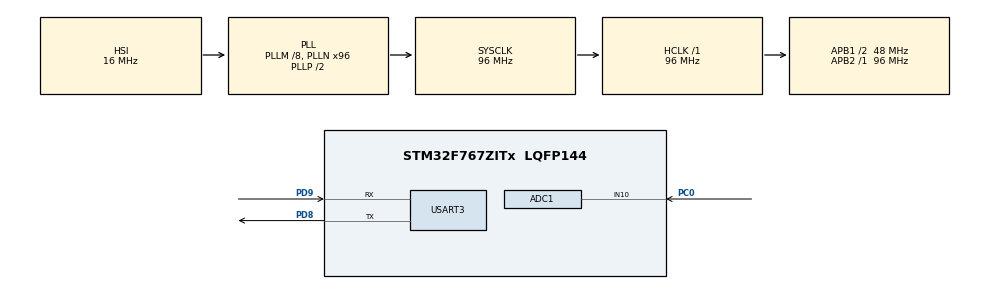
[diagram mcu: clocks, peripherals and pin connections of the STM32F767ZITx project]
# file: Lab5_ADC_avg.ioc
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ADC1.Channel-0\#ChannelRegularConversion=ADC_CHANNEL_10
ADC1.ContinuousConvMode=ENABLE
ADC1.EOCSelection=ADC_EOC_SEQ_CONV
ADC1.NbrOfConversionFlag=1
ADC1.Rank-0\#ChannelRegularConversion=1
ADC1.SamplingTime-0\#ChannelRegularConversion=ADC_SAMPLETIME_3CYCLES
ADC1.master=1
Mcu.Family=STM32F7
Mcu.Name=STM32F767ZITx
Mcu.Package=LQFP144
NVIC.PriorityGroup=NVIC_PRIORITYGROUP_4
PC0.Signal=SharedAnalog_PC0
PD8.Mode=Asynchronous
PD8.Signal=USART3_TX
PD9.Mode=Asynchronous
PD9.Signal=USART3_RX
ProjectManager.HeapSize=0x200
ProjectManager.StackSize=0x400
ProjectManager.TargetToolchain=STM32CubeIDE
RCC.48MHZClocksFreq_Value=24000000
RCC.AHBFreq_Value=96000000
RCC.APB1CLKDivider=RCC_HCLK_DIV2
RCC.APB1Freq_Value=48000000
RCC.APB1TimFreq_Value=96000000
RCC.APB2Freq_Value=96000000
RCC.APB2TimFreq_Value=96000000
RCC.CortexFreq_Value=96000000
RCC.HCLKFreq_Value=96000000
RCC.HSE_VALUE=8000000
RCC.HSI_VALUE=16000000
RCC.LSE_VALUE=32768
RCC.PLLM=8
RCC.PLLMUL=RCC_PLL_MUL9
RCC.PLLN=96
RCC.PLLQ=4
RCC.PRESCALERUSB=RCC_USBCLKSOURCE_PLL_DIV1_5
RCC.SYSCLKFreq_VALUE=96000000
RCC.SYSCLKSource=RCC_SYSCLKSOURCE_PLLCLK
RCC.SYSCLKSourceVirtual=RCC_SYSCLKSOURCE_PLLCLK
RCC.USBFreq_Value=48000000
RCC.VCOOutputFreq_Value=192000000
SH.SharedAnalog_PC0.0=GPIO_Analog
SH.SharedAnalog_PC0.1=ADC1_IN10,IN10
USART3.VirtualMode-Asynchronous=VM_ASYNC
board=NUCLEO-F767ZI

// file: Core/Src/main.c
/* USER CODE BEGIN Header */
/**
  ******************************************************************************
  * @file           : main.c
  * @brief          : Main program body
  ******************************************************************************
  * @attention
  *
  * Copyright (c) 2025 STMicroelectronics.
  * All rights reserved.
  *
  * This software is licensed under terms that can be found in the LICENSE file
  * in the root directory of this software component.
  * If no LICENSE file comes with this software, it is provided AS-IS.
  *
  ******************************************************************************
  */
/* USER CODE END Header */
#include "main.h"
#include "adc.h"
#include "usart.h"
#include "gpio.h"

/* USER CODE BEGIN Includes */
#include <stdio.h>
#include <string.h>
/* USER CODE END Includes */

/* USER CODE BEGIN PV */
volatile uint32_t adc_val = 0;
volatile uint32_t adc_val_avg_8 = 0;
volatile uint32_t adc_val_avg_16 = 0;
/* USER CODE END PV */

void SystemClock_Config(void);
/* USER CODE BEGIN PFP */
void transmitUARTStr(char* str);
void transmitUARTChar(char c);
void displayHEX(uint32_t dec);
uint32_t average_8(uint32_t x);
uint32_t average_16(uint32_t x);
/* USER CODE END PFP */

int main(void)
{

  /* MCU Configuration--------------------------------------------------------*/

  /* Reset of all peripherals, Initializes the Flash interface and the Systick. */
  HAL_Init();

  /* Configure the system clock */
  SystemClock_Config();

  /* Initialize all configured peripherals */
  MX_GPIO_Init();
  MX_ADC1_Init();
  MX_USART3_UART_Init();

  /* Infinite loop */
  /* USER CODE BEGIN WHILE */
  HAL_ADC_Start(&hadc1);
  while (1)
  {
    /* USER CODE END WHILE */

    /* USER CODE BEGIN 3 */
    while (HAL_ADC_PollForConversion(&hadc1, 100) != HAL_OK) {}
    adc_val = HAL_ADC_GetValue(&hadc1);
    adc_val_avg_8 = average_8(adc_val);
    adc_val_avg_16 = average_16(adc_val);

    transmitUARTStr("ADC1_CH10 ");

    displayHEX(adc_val);

    char buf[20];
    float v_in = adc_val/4095.0 * 3.3;
    // int int_part = (int)v_in;
    // int dec_part = (int)((v_in - int_part) * 100);

    sprintf(buf, "%.2f", v_in);
    transmitUARTStr(" Vin = ");
    transmitUARTStr(buf);
    transmitUARTStr("\r\n");
    HAL_Delay(400);
  }
  /* USER CODE END 3 */
}

void SystemClock_Config(void)
{
  RCC_OscInitTypeDef RCC_OscInitStruct = {0};
  RCC_ClkInitTypeDef RCC_ClkInitStruct = {0};

  /** Configure the main internal regulator output voltage
  */
  __HAL_RCC_PWR_CLK_ENABLE();
  __HAL_PWR_VOLTAGESCALING_CONFIG(PWR_REGULATOR_VOLTAGE_SCALE3);

  /** Initializes the RCC Oscillators according to the specified parameters
  * in the RCC_OscInitTypeDef structure.
  */
  RCC_OscInitStruct.OscillatorType = RCC_OSCILLATORTYPE_HSI;
  RCC_OscInitStruct.HSIState = RCC_HSI_ON;
  RCC_OscInitStruct.HSICalibrationValue = RCC_HSICALIBRATION_DEFAULT;
  RCC_OscInitStruct.PLL.PLLState = RCC_PLL_ON;
  RCC_OscInitStruct.PLL.PLLSource = RCC_PLLSOURCE_HSI;
  RCC_OscInitStruct.PLL.PLLM = 8;
  RCC_OscInitStruct.PLL.PLLN = 96;
  RCC_OscInitStruct.PLL.PLLP = RCC_PLLP_DIV2;
  RCC_OscInitStruct.PLL.PLLQ = 4;
  RCC_OscInitStruct.PLL.PLLR = 2;
  if (HAL_RCC_OscConfig(&RCC_OscInitStruct) != HAL_OK)
  {
    Error_Handler();
  }

  /** Activate the Over-Drive mode
  */
  if (HAL_PWREx_EnableOverDrive() != HAL_OK)
  {
    Error_Handler();
  }

  /** Initializes the CPU, AHB and APB buses clocks
  */
  RCC_ClkInitStruct.ClockType = RCC_CLOCKTYPE_HCLK|RCC_CLOCKTYPE_SYSCLK
                              |RCC_CLOCKTYPE_PCLK1|RCC_CLOCKTYPE_PCLK2;
  RCC_ClkInitStruct.SYSCLKSource = RCC_SYSCLKSOURCE_PLLCLK;
  RCC_ClkInitStruct.AHBCLKDivider = RCC_SYSCLK_DIV1;
  RCC_ClkInitStruct.APB1CLKDivider = RCC_HCLK_DIV2;
  RCC_ClkInitStruct.APB2CLKDivider = RCC_HCLK_DIV1;

  if (HAL_RCC_ClockConfig(&RCC_ClkInitStruct, FLASH_LATENCY_3) != HAL_OK)
  {
    Error_Handler();
  }
}

/* USER CODE BEGIN 4 */
void transmitUARTStr(char* str){
  while (__HAL_UART_GET_FLAG(&huart3, UART_FLAG_TC)==RESET){}
  HAL_UART_Transmit(&huart3, (uint8_t*)str, strlen(str), 1000);
}

void transmitUARTChar(char c){
  while (__HAL_UART_GET_FLAG(&huart3, UART_FLAG_TC)==RESET){}
  HAL_UART_Transmit(&huart3, (uint8_t*)&c, 1, 1000);
}

void displayHEX(uint32_t dec){
  char buf[13];
  sprintf(buf, "0x%08x", (unsigned int)dec);
  transmitUARTStr(buf);
}

uint32_t average_8(uint32_t x){
  static uint32_t samples[8];
  static int i = 0;
  static uint32_t total = 0;

  total += x - samples[i];
  samples[i] = x;

  i = ((i == 7) ? 0 : i+1);

  return total >> 3;
}

uint32_t average_16(uint32_t x){
  static uint32_t samples[16];
  static int i = 0;
  static uint32_t total = 0;

  total += x - samples[i];
  samples[i] = x;

  i = ((i == 15) ? 0 : i+1);

  return total >> 4;
}
/* USER CODE END 4 */

void Error_Handler(void)
{
  __disable_irq();
  while (1)
  {
  }
}
